# STM32G474xx register map
File version: 1.4
CPU: CM4 r0p1, little endian, MPU, FPU, 4 interrupt priority bits
Registers are 32-bit, read-write, reset 0x0 unless marked. A register's access mark holds for its fields unless they carry their own. Offsets are from the block's base; [hi:lo] are bit positions; {n}, {i} and the like mark numbered series; 'fields as' and 'values as' point back to an identical list.

## SYSCFG — System configuration controller
Base 0x40010000
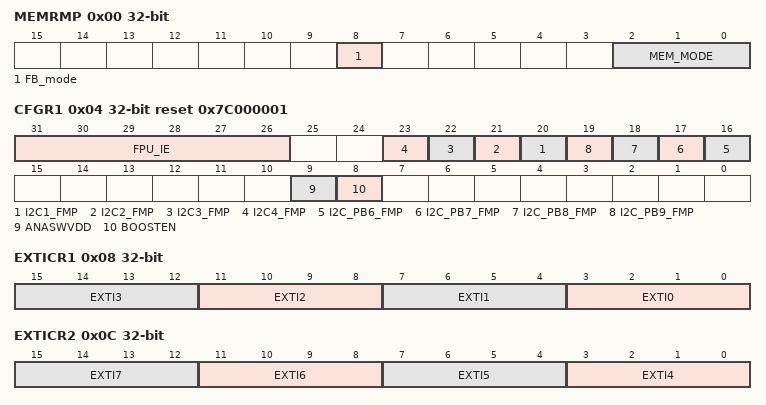
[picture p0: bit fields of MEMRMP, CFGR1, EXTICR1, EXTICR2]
0x00 MEMRMP — Remap Memory register
  [8] FB_mode — User Flash Bank mode
  [2:0] MEM_MODE — Memory mapping selection
0x04 CFGR1 reset 0x7C000001 — peripheral mode configuration register
  [31:26] FPU_IE — FPU Interrupts Enable
  [n+19] I2C{n}_FMP (n=1..4) — I2C1 FM+ drive capability enable
  [n+10] I2C_PB{n}_FMP (n=6..9) — FM+ drive capability on PB6
  [9] ANASWVDD — GPIO analog switch control voltage selection
  [8] BOOSTEN
0x08 EXTICR1 — external interrupt configuration register 1
  [4n+3:4n] EXTI{n} (n=0..3) — EXTI x configuration (x = 0 to 3)
0x0C EXTICR2 — external interrupt configuration register 2
  [4n-13:4n-16] EXTI{n} (n=4..7) — EXTI x configuration (x = 4 to 7)
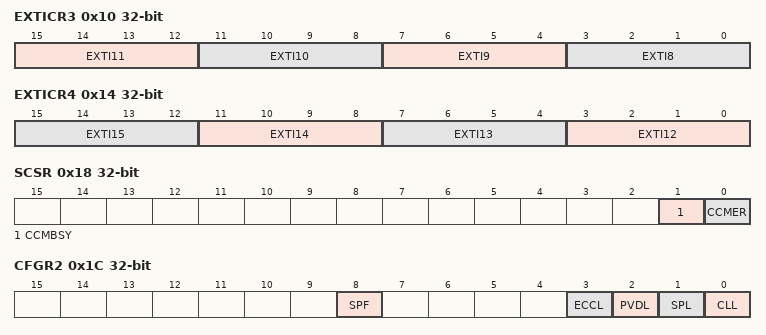
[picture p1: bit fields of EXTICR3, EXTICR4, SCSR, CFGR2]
0x10 EXTICR3 — external interrupt configuration register 3
  [15:12] EXTI11 — EXTI x configuration (x = 8 to 11)
  [11:8] EXTI10
  [7:4] EXTI9 — EXTI x configuration (x = 8 to 11)
  [3:0] EXTI8 — EXTI x configuration (x = 8 to 11)
0x14 EXTICR4 — external interrupt configuration register 4
  [4n-45:4n-48] EXTI{n} (n=12..15) — EXTI x configuration (x = 12 to 15)
0x18 SCSR access per field — CCM SRAM control and status register
  [1] CCMBSY ro — CCM SRAM busy by erase operation
  [0] CCMER rw — CCM SRAM Erase
0x1C CFGR2 — configuration register 2
  [8] SPF — SRAM Parity Flag
  [3] ECCL — ECC Lock
  [2] PVDL — PVD Lock
  [1] SPL — SRAM Parity Lock
  [0] CLL — Core Lockup Lock
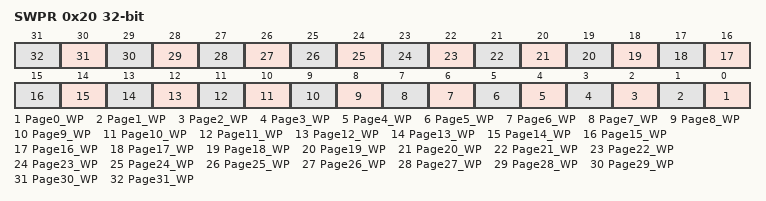
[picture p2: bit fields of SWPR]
0x20 SWPR — SRAM Write protection register 1
  [n] Page{n}_WP (n=0..31) — Write protection
0x24 SKR wo — SRAM2 Key Register
  [7:0] KEY — SRAM2 Key for software erase

## VREFBUF — Voltage reference buffer
Base 0x40010030
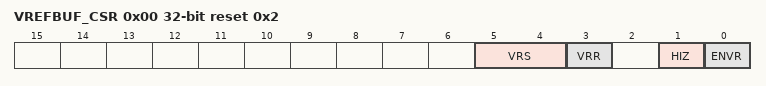
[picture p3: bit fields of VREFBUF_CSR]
0x00 VREFBUF_CSR access per field reset 0x2 — VREF_BUF Control and Status Register
  [5:4] VRS rw — Voltage reference scale
  [3] VRR ro — Voltage reference buffer ready
  [1] HIZ rw — High impedence mode for the VREF_BUF
  [0] ENVR rw — Enable Voltage Reference
0x04 VREFBUF_CCR — VREF_BUF Calibration Control Register
  [5:0] TRIM — Trimming code

## COMP — Comparator control and status register
Base 0x40010200
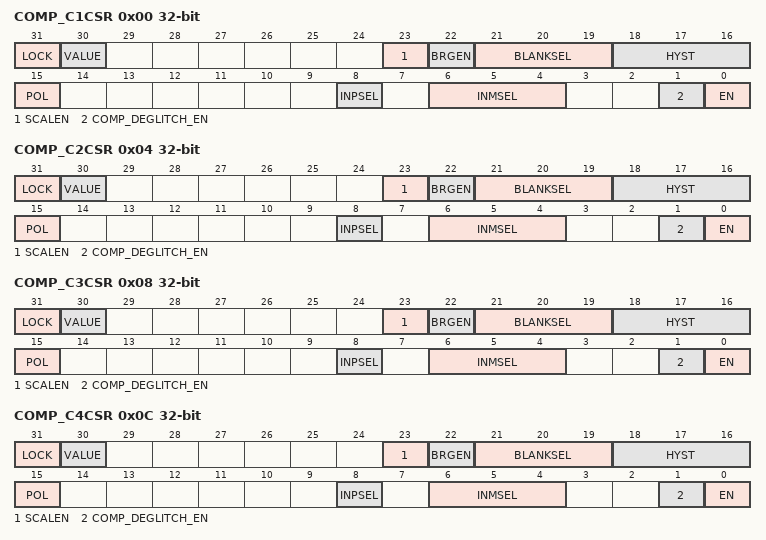
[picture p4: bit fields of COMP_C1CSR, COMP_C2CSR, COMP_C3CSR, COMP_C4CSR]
0x00 COMP_C1CSR access per field — Comparator control/status register
  [31] LOCK rw, [30] VALUE ro, [23] SCALEN rw, [22] BRGEN rw, [21:19] BLANKSEL rw, [18:16] HYST rw, [15] POL rw, [8] INPSEL rw, [6:4] INMSEL rw, [1] COMP_DEGLITCH_EN rw, [0] EN rw
0x04 COMP_C2CSR access per field — Comparator control/status register
  fields as COMP_C1CSR
0x08 COMP_C3CSR access per field — Comparator control/status register
  fields as COMP_C1CSR
0x0C COMP_C4CSR access per field — Comparator control/status register
  fields as COMP_C1CSR
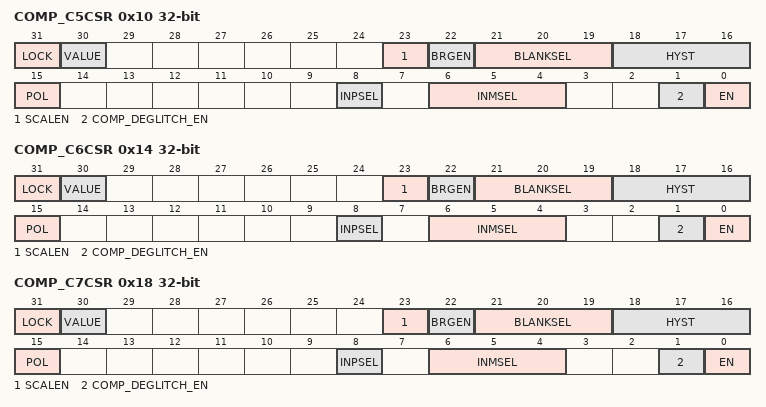
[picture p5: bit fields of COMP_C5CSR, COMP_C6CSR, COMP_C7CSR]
0x10 COMP_C5CSR access per field — Comparator control/status register
  fields as COMP_C1CSR
0x14 COMP_C6CSR access per field — Comparator control/status register
  fields as COMP_C1CSR
0x18 COMP_C7CSR access per field — Comparator control/status register
  fields as COMP_C1CSR

## OPAMP — Operational amplifiers
Base 0x40010300
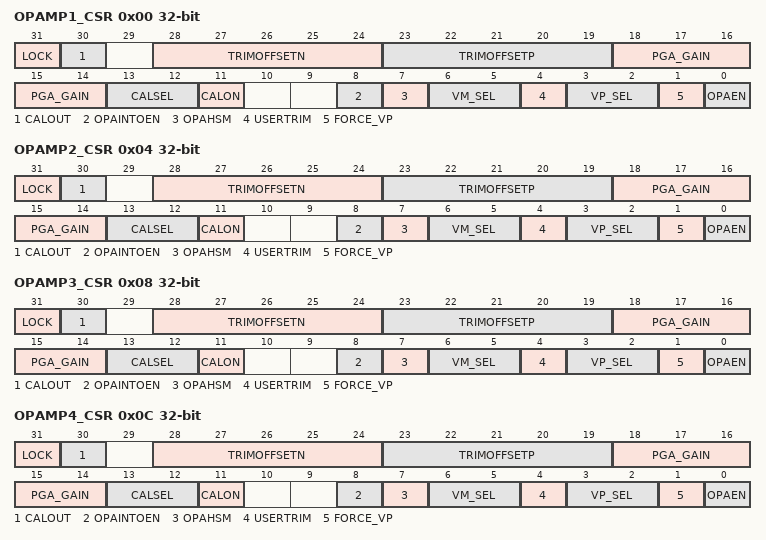
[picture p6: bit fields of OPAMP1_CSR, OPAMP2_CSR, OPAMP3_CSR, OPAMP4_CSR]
0x00 OPAMP1_CSR — OPAMP1 control/status register
  [31] LOCK
  [30] CALOUT
  [28:24] TRIMOFFSETN
  [23:19] TRIMOFFSETP
  [18:14] PGA_GAIN
  [13:12] CALSEL
  [11] CALON
  [8] OPAINTOEN
  [7] OPAHSM
  [6:5] VM_SEL
  [4] USERTRIM
  [3:2] VP_SEL
  [1] FORCE_VP
  [0] OPAEN — Operational amplifier Enable
0x04 OPAMP2_CSR — OPAMP2 control/status register
  fields as OPAMP1_CSR
0x08 OPAMP3_CSR — OPAMP3 control/status register
  fields as OPAMP1_CSR
0x0C OPAMP4_CSR — OPAMP4 control/status register
  fields as OPAMP1_CSR
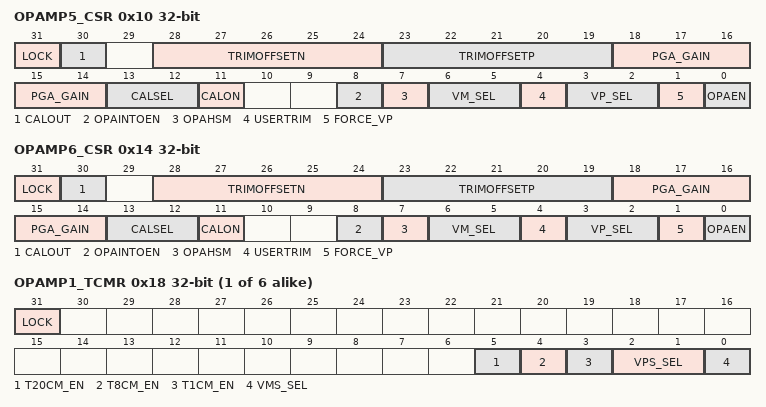
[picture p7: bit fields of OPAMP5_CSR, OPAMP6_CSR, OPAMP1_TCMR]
0x10 OPAMP5_CSR — OPAMP5 control/status register
  fields as OPAMP1_CSR
0x14 OPAMP6_CSR — OPAMP6 control/status register
  fields as OPAMP1_CSR
{0x14+4i} OPAMP{i}_TCMR (i=1..6) — OPAMP{i} control/status register
  [31] LOCK, [5] T20CM_EN, [4] T8CM_EN, [3] T1CM_EN, [2:1] VPS_SEL, [0] VMS_SEL
